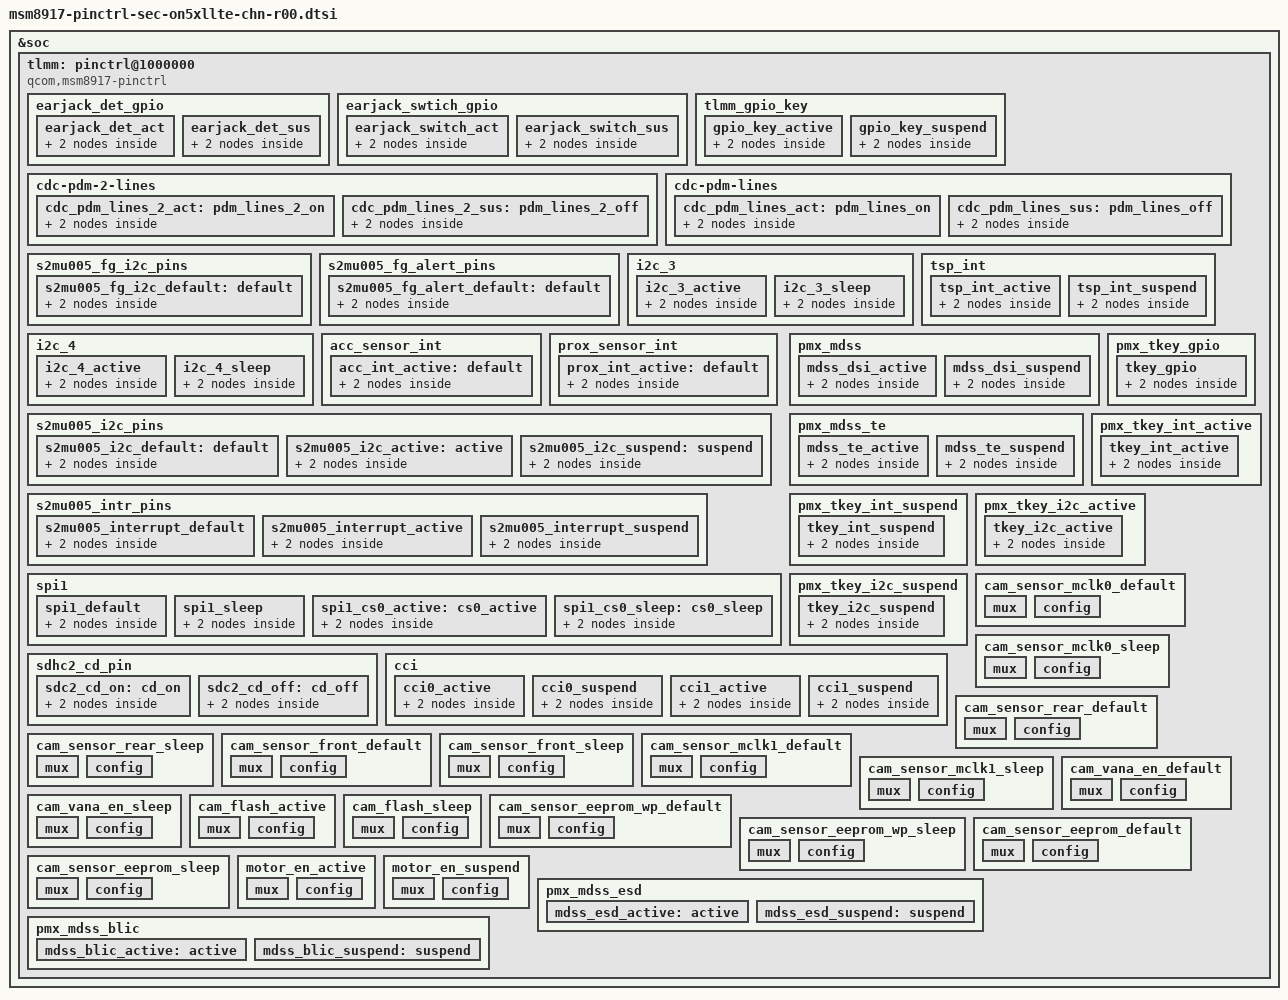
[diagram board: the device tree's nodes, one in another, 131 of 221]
/*
 * Copyright (c) 2015, The Linux Foundation. All rights reserved.
 *
 * This program is free software; you can redistribute it and/or modify
 * it under the terms of the GNU General Public License version 2 and
 * only version 2 as published by the Free Software Foundation.
 *
 * This program is distributed in the hope that it will be useful,
 * but WITHOUT ANY WARRANTY; without even the implied warranty of
 * MERCHANTABILITY or FITNESS FOR A PARTICULAR PURPOSE.  See the
 * GNU General Public License for more details.
 */

/* #include "../../qcom/msm8917-pinctrl.dtsi" */

&soc {
	tlmm: pinctrl@1000000 {
		compatible = "qcom,msm8917-pinctrl";
		reg = <0x1000000 0x300000>;
		interrupts = <0 208 0>;
		gpio-controller;
		#gpio-cells = <2>;
		interrupt-controller;
		#interrupt-cells = <2>;

		earjack_det_gpio {
			earjack_det_act: earjack_det_act {
				mux {
					pins = "gpio61";
					function = "gpio";
				};

				config {
					pins = "gpio61";
					drive-strength = <2>;
					bias-disable;
				};
			};
			earjack_det_sus: earjack_det_sus {
				mux {
					pins = "gpio61";
					function = "gpio";
				};

				config {
					pins = "gpio61";
					drive-strength = <2>;
					bias-disable;
				};
			};
		};

		earjack_swtich_gpio {
			earjack_switch_act: earjack_switch_act {
				mux {
					pins = "gpio93";
					function = "gpio";
				};

				config {
					pins = "gpio93";
					drive-strength = <2>;
					bias-disable;
				};
			};
			earjack_switch_sus: earjack_switch_sus {
				mux {
					pins = "gpio93";
					function = "gpio";
				};

				config {
					pins = "gpio93";
					drive-strength = <2>;
					bias-disable;
				};
			};
		};
		
		tlmm_gpio_key {
			gpio_key_active: gpio_key_active {
				mux {
					pins = "gpio127","gpio128";
					function = "gpio";
				};

				config {
					pins = "gpio127","gpio128";
					drive-strength = <2>;
					bias-pull-up;
				};
			};

			gpio_key_suspend: gpio_key_suspend {
				mux {
					pins = "gpio127","gpio128";
					function = "gpio";
				};

				config {
					pins = "gpio127","gpio128";
					drive-strength = <2>;
					bias-pull-up;
				};
			};
		};
		
		cdc-pdm-2-lines {
			cdc_pdm_lines_2_act: pdm_lines_2_on {
				mux {
					pins = "gpio70", "gpio71", "gpio72";
					function = "cdc_pdm0";
				};

				config {
					pins = "gpio70", "gpio71", "gpio72";
					drive-strength = <8>;
					bias-pull-down;
				};
			};

			cdc_pdm_lines_2_sus: pdm_lines_2_off {
				mux {
					pins = "gpio70", "gpio71", "gpio72";
					function = "cdc_pdm0";
				};

				config {
					pins = "gpio70", "gpio71", "gpio72";
					drive-strength = <2>;
					bias-pull-down;
				};
			};
		};

		cdc-pdm-lines {
			cdc_pdm_lines_act: pdm_lines_on {
				mux {
					pins = "gpio69", "gpio73", "gpio74";
					function = "cdc_pdm0";
				};

				config {
					pins = "gpio69", "gpio73", "gpio74";
					drive-strength = <8>;
					bias-pull-down;
				};
			};
			cdc_pdm_lines_sus: pdm_lines_off {
				mux {
					pins = "gpio69", "gpio73", "gpio74";
					function = "cdc_pdm0";
				};

				config {
					pins = "gpio69", "gpio73", "gpio74";
					drive-strength = <2>;
					bias-pull-down;
				};
			};
		};

		/* Fuelgauge I2C pins */
		s2mu005_fg_i2c_pins {

			s2mu005_fg_i2c_default: default {
				/* default state */
				mux {
					pins = "gpio6", "gpio7";
					function = "gpio";
				};

				config {
					pins = "gpio6", "gpio7";
					drive-strength = <2>;
					bias-disable;
				};
			};

		};

		/* Fuelgauge alert pin */
                s2mu005_fg_alert_pins {

                        s2mu005_fg_alert_default: default {
                                /* default state */
                                mux {
                                        pins = "gpio63";
                                        function = "gpio";
                                };

                                config {
                                        pins = "gpio63";
                                        drive-strength = <2>;
                                        bias-disable;
                                };
                        };

                };
		
		/* pingrp for tsp - start */
		i2c_3 {
			i2c_3_active: i2c_3_active {
				/* active state */
				mux {
					pins = "gpio10", "gpio11";
					function = "blsp_i2c3";
				};

				config {
					pins = "gpio10", "gpio11";
					drive-strength = <2>;
					bias-disable;
				};
			};

			i2c_3_sleep: i2c_3_sleep {
				/* suspended state */
				mux {
					pins = "gpio10", "gpio11";
					function = "blsp_i2c3";
				};

				config {
					pins = "gpio10", "gpio11";
					drive-strength = <2>;
					bias-disable;
				};
			};
		};

		tsp_int {
			tsp_int_active: tsp_int_active {
				mux {
					pins = "gpio65";
					function = "gpio";
				};

				config {
					pins = "gpio65";
					drive-strength = <2>;
					bias-disable;
				};
			};		
			tsp_int_suspend: tsp_int_suspend {
				mux {
					pins = "gpio65";
					function = "gpio";
				};

				config {
					pins = "gpio65";
					drive-strength = <2>;
					bias-disable;
				};
			};
		};

		/* pingrp for sensor - start */
		i2c_4 {
			i2c_4_active: i2c_4_active {
				/* active state */
				mux {
					pins = "gpio14", "gpio15";
					function = "blsp_i2c4";
				};

				config {
					pins = "gpio14", "gpio15";
					drive-strength = <2>;
					bias-disable;
				};
			};

			i2c_4_sleep: i2c_4_sleep {
				/* suspended state */
				mux {
					pins = "gpio14", "gpio15";
					function = "blsp_i2c4";
				};

				config {
					pins = "gpio14", "gpio15";
					drive-strength = <2>;
					bias-disable;
				};
			};
		};

		acc_sensor_int {
			acc_int_active: default {
				mux {
					pins = "gpio42";
					function = "gpio";
				};

				config {
					pins = "gpio42";
					drive-strength = <2>;
					bias-pull-down;
				};
			};
		};
		prox_sensor_int {
			prox_int_active: default {
				mux {
					pins = "gpio43";
					function = "gpio";
				};

				config {
					pins = "gpio43";
					drive-strength = <2>;
					bias-disable;
				};
			};
		};
		/* pingrp for sensor - end */

			/* MUIC - S2MU005 */
		s2mu005_i2c_pins {
			s2mu005_i2c_default: default {
				/* default state*/
				mux {
					pins = "gpio18", "gpio19"; /* SDA, SCL */
                        		function = "gpio";
				};
				config {
					pins = "gpio18", "gpio19";
					drive-strength = <2>;
					bias-disable;
				};
			};
	
			s2mu005_i2c_active: active {
				/*active state*/
				 mux {
                                        pins = "gpio18", "gpio19"; /* SDA, SCL */
                                        function = "gpio";
                                };
                                config {
                                        pins = "gpio18", "gpio19";
                                        drive-strength = <2>;
                                        bias-disable;
                                };
		
			};
			s2mu005_i2c_suspend: suspend {
				/*suspend state*/
				 mux {
                                        pins = "gpio18", "gpio19"; /* SDA, SCL */
                                        function = "gpio";
                                };
                                config {
                                        pins = "gpio18", "gpio19";
                                        drive-strength = <2>;
                                        bias-disable;
                                };

			};
		};

		s2mu005_intr_pins {
			s2mu005_interrupt_default: s2mu005_interrupt_default {
				/*default state*/
				mux {
					pins = "gpio35";
					function = "gpio";
				};
				config {
					pins = "gpio35";
					drive-strength = <2>;
					bias-disable;
				};
			};

			s2mu005_interrupt_active: s2mu005_interrupt_active {
				/*active state*/
				mux {
                                        pins = "gpio35";
                                        function = "gpio";
                                };
                                config {
                                        pins = "gpio35";
                                        drive-strength = <2>;
                                        bias-disable;
                                };
		
			};
			s2mu005_interrupt_suspend: s2mu005_interrupt_suspend {
				/*suspend state*/
				 mux {
                                        pins = "gpio35";
                                        function = "gpio";
                                };
                                config {
                                        pins = "gpio35";
                                        drive-strength = <2>;
                                        bias-disable;
                                };
			};
		};

		spi1 {
			spi1_default: spi1_default {
				/* active state */
				mux {
					/* MOSI, MISO, CLK */
					pins = "gpio0", "gpio1", "gpio3";
					function = "blsp_spi1";
				};

				config {
					pins = "gpio0", "gpio1", "gpio3";
					drive-strength = <2>; /* 12 MA */
					bias-disable = <0>; /* No PULL */
					input-low;
				};
			};

			spi1_sleep: spi1_sleep {
				/* suspended state */
				mux {
					/* MOSI, MISO, CLK */
					pins = "gpio0", "gpio1", "gpio3";
					function = "gpio";
				};

				config {
					pins = "gpio0", "gpio1", "gpio3";
					drive-strength = <2>; /* 2 MA */
					bias-pull-down; /* PULL Down */
					input-low;
				};
			};

			spi1_cs0_active: cs0_active {
				/* CS */
				mux {
					pins = "gpio2";
					function = "blsp_spi1";
				};

				config {
					pins = "gpio2";
					drive-strength = <2>;
					bias-disable = <0>;
				};
			};

			spi1_cs0_sleep: cs0_sleep {
				/* CS */
				mux {
					pins = "gpio2";
					function = "gpio";
				};

				config {
					pins = "gpio2";
					drive-strength = <2>;
					bias-disable = <0>;
				};
			};
		};
		
		pmx_mdss: pmx_mdss {
			/* IN_CELL panel control LCD & TSP power at the same time */
			mdss_dsi_active: mdss_dsi_active {
				mux {
					pins = 
					/* LCD */
					"gpio60", "gpio64", "gpio95",
					/* BLIC */
					"gpio22", "gpio23", "gpio89", "gpio90", "gpio94";

					function = "gpio";
				};

				config {
					pins = 
					/* LCD */
					"gpio60", "gpio64", "gpio95",
					/* BLIC */
					"gpio22", "gpio23", "gpio89", "gpio90", "gpio94";

					drive-strength = <8>; /* 8 mA */
					bias-disable; /* no pull */
					output-low;
				};
			};
			mdss_dsi_suspend: mdss_dsi_suspend {
				mux {
					pins = 
					/* LCD */
					"gpio60", "gpio64", "gpio95",
					/* BLIC */
					"gpio22", "gpio23", "gpio89", "gpio90", "gpio94";

					function = "gpio";
				};

				config {
					pins = 
					/* LCD */
					"gpio60", "gpio64", "gpio95",
					/* BLIC */
					"gpio22", "gpio23", "gpio89", "gpio90", "gpio94";

					drive-strength = <2>; /* 2 mA */
					bias-pull-down; /* pull down */
					output-low;
				};
			};
		};

		pmx_mdss_te: pmx_mdss_te {
			mdss_te_active: mdss_te_active {
				mux {
					pins = "gpio24";
					function = "mdp_vsync";
				};
				config {
					pins = "gpio24";
					drive-strength = <2>; /* 8 mA */
					bias-pull-down; /* pull down*/
				};
			};

			mdss_te_suspend: mdss_te_suspend {
				mux {
					pins = "gpio24";
					function = "mdp_vsync";
				};
				config {
					pins = "gpio24";
					drive-strength = <2>; /* 2 mA */
					bias-pull-down; /* pull down */
				};
			};
		};

		/* add pingrp for touchkey */
		pmx_tkey_gpio {
			tkey_gpio: tkey_gpio {
				mux {
					pins = "gpio92";
					function = "gpio";
				};

				config {
					pins = "gpio92";
					drive-strength = <2>;
					bias-disable;
				};
			};
		};

		pmx_tkey_int_active {
			tkey_int_active: tkey_int_active {
				mux {
					pins = "gpio48";
					function = "gpio";
				};

				config {
					pins = "gpio48";
					drive-strength = <8>;
					bias-pull-up;
				};
			};
		};

		pmx_tkey_int_suspend {
			tkey_int_suspend: tkey_int_suspend {
				mux {
					pins = "gpio48";
					function = "gpio";
				};

				config {
					pins = "gpio48";
					drive-strength = <2>;
					bias-pull-down;
				};
			};
		};

		pmx_tkey_i2c_active {
			tkey_i2c_active: tkey_i2c_active {
				mux {
					pins = "gpio98",  "gpio99";
					function = "gpio";
				};

				config {
					pins = "gpio98",  "gpio99";
					drive-strength = <8>;
					bias-pull-up;
				};
			};
		};

		pmx_tkey_i2c_suspend {
			tkey_i2c_suspend: tkey_i2c_suspend {
				mux {
					pins = "gpio98",  "gpio99";
					function = "gpio";
				};

				config {
					pins = "gpio98",  "gpio99";
					drive-strength = <2>;
					bias-pull-down;
				};
			};
		};

		sdhc2_cd_pin {
			sdc2_cd_on: cd_on {
				mux {
					pins = "gpio67";
					function = "gpio";
				};

				config {
					pins = "gpio67";
					drive-strength = <2>;
					bias-disable;
				};
			};

			sdc2_cd_off: cd_off {
				mux {
					pins = "gpio67";
					function = "gpio";
				};

				config {
					pins = "gpio67";
					drive-strength = <2>;
					bias-disable;
				};
			};
		};

		cci {
			cci0_active: cci0_active {
				/* cci0 active state */
				mux {
					/* CLK, DATA */
					pins = "gpio29", "gpio30";
					function = "cci_i2c";
				};

				config {
					pins = "gpio29", "gpio30";
					drive-strength = <2>; /* 2 MA */
					bias-disable; /* No PULL */
				};
			};

			cci0_suspend: cci0_suspend {
				/* cci0 suspended state */
				mux {
					/* CLK, DATA */
					pins = "gpio29", "gpio30";
					function = "gpio";
				};

				config {
					pins = "gpio29", "gpio30";
					drive-strength = <2>; /* 2 MA */
					bias-disable; /* No PULL */
				};
			};

			cci1_active: cci1_active {
				/* cci1 active state */
				mux {
					/* CLK, DATA */
					pins = "gpio31", "gpio32";
					function = "cci_i2c";
				};

				config {
					pins = "gpio31", "gpio32";
					drive-strength = <2>; /* 2 MA */
					bias-disable; /* No PULL */
				};
			};

			cci1_suspend: cci1_suspend {
				/* cci1 suspended state */
				mux {
					/* CLK, DATA */
					pins = "gpio31", "gpio32";
					function = "gpio";
				};

				config {
					pins = "gpio31", "gpio32";
					drive-strength = <2>; /* 2 MA */
					bias-disable; /* No PULL */
				};
			};
		};
		

		/*sensors */
		cam_sensor_mclk0_default: cam_sensor_mclk0_default {
			/* MCLK0 */
			mux {
				/* CLK, DATA */
				pins = "gpio26";
				function = "cam_mclk";
			};

			config {
				pins = "gpio26";
				bias-disable; /* No PULL */
				drive-strength = <2>; /* 2 MA */
			};
		};

		cam_sensor_mclk0_sleep: cam_sensor_mclk0_sleep {
			/* MCLK0 */
			mux {
				/* CLK, DATA */
				pins = "gpio26";
				function = "cam_mclk";
			};

			config {
				pins = "gpio26";
				bias-pull-down; /* PULL DOWN */
				drive-strength = <2>; /* 4 MA */
				output-low;
			};
		};

		cam_sensor_rear_default: cam_sensor_rear_default {
			/* RESET, STANDBY */
			mux {
				pins = "gpio36";
				function = "gpio";
			};

			config {
				pins = "gpio36";
				bias-disable; /* No PULL */
				drive-strength = <2>; /* 2 MA */
			};
		};

		cam_sensor_rear_sleep: cam_sensor_rear_sleep {
			/* RESET, STANDBY */
			mux {
				pins = "gpio36";
				function = "gpio";
			};

			config {
				pins = "gpio36";
				bias-disable; /* No PULL */
				drive-strength = <2>; /* 2 MA */
			};
		};

		cam_sensor_front_default: cam_sensor_front_default {
			/* RESET, STANDBY */
			mux {
				pins = "gpio38";
				function = "gpio";
			};

			config {
				pins = "gpio38";
				bias-disable; /* No PULL */
				drive-strength = <2>; /* 2 MA */
			};
		};

		cam_sensor_front_sleep: cam_sensor_front_sleep {
			/* RESET, STANDBY */
			mux {
				pins = "gpio38";
				function = "gpio";
			};

			config {
				pins = "gpio38";
				bias-disable; /* No PULL */
				drive-strength = <2>; /* 2 MA */
			};
		};

		cam_sensor_mclk1_default: cam_sensor_mclk1_default {
			/* MCLK1 */
			mux {
				/* CLK, DATA */
				pins = "gpio27";
				function = "cam_mclk";
			};

			config {
				pins = "gpio27";
				bias-disable; /* No PULL */
				drive-strength = <4>; /* MA */
			};
		};

		cam_sensor_mclk1_sleep: cam_sensor_mclk1_sleep {
			/* MCLK1 */
			mux {
				/* CLK, DATA */
				pins = "gpio27";
				function = "gpio";
			};

			config {
				pins = "gpio27";
				bias-disable; /* NO PULL */
				drive-strength = <4>; /* MA */
				output-low;
			};
		};

		cam_vana_en_default: cam_vana_en_default {
			/* VANA */
			mux {
				pins = "gpio9";
				function = "gpio";
			};

			config {
				pins = "gpio9";
				bias-disable;
				drive-strength = <2>;
				output-low;
			};
		};

		cam_vana_en_sleep: cam_vana_en_sleep {
			/* VDIG */
			mux {
				pins = "gpio9";
				function = "gpio";
			};

			config {
				pins = "gpio9";
				bias-pull-down;
				drive-strength = <2>;
				output-low;
			};
		};

		cam_flash_active: cam_flash_active {
			/* TORCH, FLASH */
			mux {
				pins = "gpio34", "gpio33";
				function = "gpio";
			};

			config {
				pins = "gpio34", "gpio33";
				bias-pull-down; /* PULL DOWN */
				drive-strength = <2>; /* 2 MA */
				output-low;
			};
		};

		cam_flash_sleep: cam_flash_sleep {
			/* TORCH, FLASH */
			mux {
				pins = "gpio34", "gpio33";
				function = "gpio";
			};

			config {
				pins = "gpio34", "gpio33";
				bias-pull-down; /* PULL DOWN */
				drive-strength = <2>; /* 2 MA */
				output-low;
			};
		};


		cam_sensor_eeprom_wp_default: cam_sensor_eeprom_wp_default {
			mux {
				pins = "gpio85";
				function = "gpio";
			};

			config {
				pins = "gpio85";
				bias-disable;
				drive-strength = <4>;
				output-low;
			};
		};

		cam_sensor_eeprom_wp_sleep: cam_sensor_eeprom_wp_sleep {
			mux {
				pins = "gpio85";
				function = "gpio";
			};

			config {
				pins = "gpio85";
				bias-pull-down;
				drive-strength = <4>;
				output-low;
			};
		};

		cam_sensor_eeprom_default: cam_sensor_eeprom_default {
			mux {
				pins = "gpio22", "gpio23";
				function = "gpio";
			};

			config {
				pins = "gpio22", "gpio23";
				bias-disable;
				drive-strength = <4>;
				output-low;
			};
		};

		cam_sensor_eeprom_sleep: cam_sensor_eeprom_sleep {
			mux {
				pins = "gpio22", "gpio23";
				function = "gpio";
			};

			config {
				pins = "gpio22", "gpio23";
				bias-pull-down;
				drive-strength = <4>;
				output-low;
			};
		};

		/* add pinctrl for motor  */
		motor_en_active: motor_en_active {
			mux {
				pins = "gpio40";
				function = "gpio";			
			};

			config {
				pins = "gpio40";
				bias-pull-down;
				drive-strength = <2>;
				output-high;
			};
		};

		motor_en_suspend: motor_en_suspend {
			mux {
				pins = "gpio40";
				function = "gpio";			
			};

			config {
				pins = "gpio40";
				bias-pull-down;
				drive-strength = <2>;
				output-low;
			};
		};

		pmx_mdss_esd: pmx_mdss_esd {
			label = "mdss-esd-pin";
			qcom,pin-func = <0>;
			mdss_esd_active: active {
				drive-strength = <2>;
				bias-disable; /* No PULL */
				//bias-pull-down; /* pull down */
			};
			mdss_esd_suspend: suspend {
				drive-strength = <2>;
				bias-disable; /* No PULL */
				//bias-pull-down; /* pull down */
			};
		};

		pmx_mdss_blic: pmx_mdss_blic {			// i2c scl & sda lane
			label = "mdss-blic-pins";
			qcom,pin-func = <0>;
			mdss_blic_active: active {
				drive-strength = <8>; /* 8 mA */
				bias-disable; /* No PULL */
				output-high;
			};
			mdss_blic_suspend: suspend {
				drive-strength = <2>; /* 2 mA */
				bias-disable; /* No PULL */
				output-low;
			};
		};
	};
};
